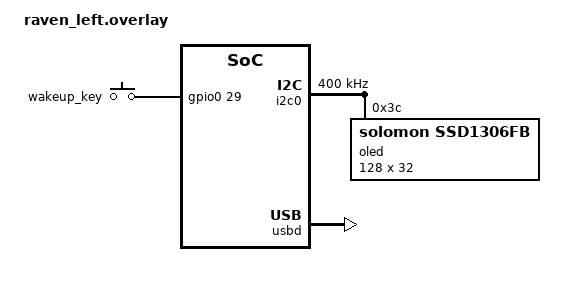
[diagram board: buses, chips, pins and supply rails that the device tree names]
// Devicetree overlays are processed before Kconfig symbols are available.
// Select the shared handwire keymap explicitly in this preprocessing pass.
#define RAVEN_LEFT_HANDWIRE 1

#include "raven.dtsi"
#include "raven-pinctrl.dtsi"

// Physical 6-column x 4-row layout, viewed from the keycap side.
// Electrical columns run right to left; RC(0,0) is the top-right T key.
&default_transform {
    columns = <12>;
    rows = <4>;
    map = <
        RC(0,5) RC(0,4) RC(0,3) RC(0,2) RC(0,1) RC(0,0) RC(0,6) RC(0,7) RC(0,8) RC(0,9) RC(0,10) RC(0,11)
        RC(1,5) RC(1,4) RC(1,3) RC(1,2) RC(1,1) RC(1,0) RC(1,6) RC(1,7) RC(1,8) RC(1,9) RC(1,10) RC(1,11)
        RC(2,5) RC(2,4) RC(2,3) RC(2,2) RC(2,1) RC(2,0) RC(2,6) RC(2,7) RC(2,8) RC(2,9) RC(2,10) RC(2,11)
        RC(3,5) RC(3,4) RC(3,3) RC(3,2) RC(3,1) RC(3,0) RC(3,6) RC(3,7) RC(3,8) RC(3,9) RC(3,10) RC(3,11)
    >;
};

&kscan0 {
    // Physical rows are sensed; physical columns are driven.
    // T anchor: drive P1.13 -> diode -> switch -> sense P0.31.
    diode-direction = "col2row";
    // Physical rows, top to bottom.
    row-gpios = <&gpio0 31 (GPIO_ACTIVE_HIGH | GPIO_PULL_DOWN)>,
                <&gpio0 29 (GPIO_ACTIVE_HIGH | GPIO_PULL_DOWN)>,
                <&gpio0 2  (GPIO_ACTIVE_HIGH | GPIO_PULL_DOWN)>,
                <&gpio1 15 (GPIO_ACTIVE_HIGH | GPIO_PULL_DOWN)>;

    // Physical columns, right to left, starting at T.
    col-gpios = <&gpio1 13 GPIO_ACTIVE_HIGH>,
                <&gpio1 11 GPIO_ACTIVE_HIGH>,
                <&gpio0 10 GPIO_ACTIVE_HIGH>,
                <&gpio0 9  GPIO_ACTIVE_HIGH>,
                <&gpio1 6  GPIO_ACTIVE_HIGH>,
                <&gpio1 4  GPIO_ACTIVE_HIGH>;
};

// Wake with F: physical second row, second column from the right.
// Drive its column P1.11 and sense its row P0.29.
&wakeup_key {
    gpios = <&gpio0 29 (GPIO_ACTIVE_HIGH | GPIO_PULL_DOWN)>;
};

&wakeup_trigger {
    extra-gpios = <&gpio1 11 GPIO_ACTIVE_HIGH>;
};

// Keep UART disabled during left-handwire testing.
&uart0 {
    status = "disabled";
};

&i2c0 {
    compatible = "nordic,nrf-twi";
    status = "okay";
    pinctrl-0 = <&i2c0_default>;
    pinctrl-1 = <&i2c0_sleep>;
    pinctrl-names = "default", "sleep";
    clock-frequency = <I2C_BITRATE_FAST>;

    oled: ssd1306@3c {
        compatible = "solomon,ssd1306fb";
        reg = <0x3c>;
        width = <128>;
        height = <32>;
        segment-offset = <0>;
        page-offset = <0>;
        display-offset = <0>;
        multiplex-ratio = <31>;
        com-sequential;
        prechargep = <0x22>;
        inversion-on;
    };
};


zephyr_udc0: &usbd {
    status = "okay";
};


